AUTOSAR XML (schema 00048)
package /HuaweiMDC/PlatformApplication/UssCmCenterApplication/Execution
  executable libuss_a_cm
    root sw component prototype uss_a_cm: application-type=libuss_a_cm
package /HuaweiMDC/PlatformApplication/UssCmCenterApplication/SwComponent
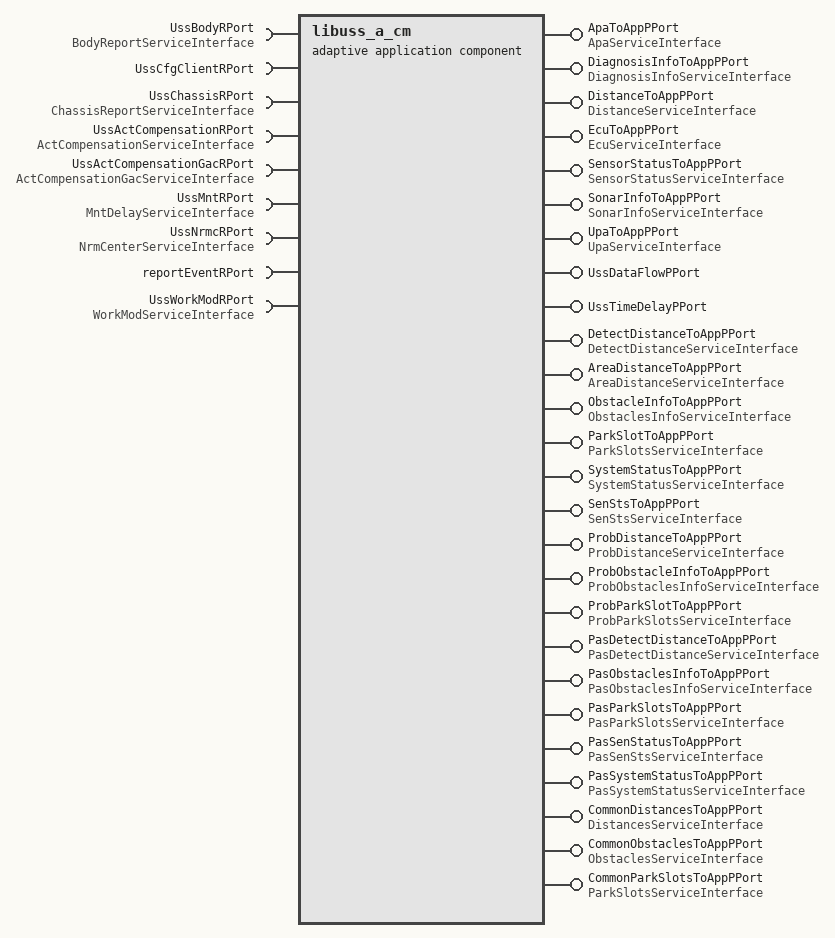
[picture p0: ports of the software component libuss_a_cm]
  adaptive application sw component type libuss_a_cm
    7 x provide port:
      ApaToAppPPort: provided-interface=ApaServiceInterface
      DiagnosisInfoToAppPPort: provided-interface=DiagnosisInfoServiceInterface
      DistanceToAppPPort: provided-interface=DistanceServiceInterface
      EcuToAppPPort: provided-interface=EcuServiceInterface
      SensorStatusToAppPPort: provided-interface=SensorStatusServiceInterface
      SonarInfoToAppPPort: provided-interface=SonarInfoServiceInterface
      UpaToAppPPort: provided-interface=UpaServiceInterface
    5 x require port:
      UssBodyRPort: required-interface=BodyReportServiceInterface
      UssCfgClientRPort
      UssChassisRPort: required-interface=ChassisReportServiceInterface
      UssActCompensationRPort: required-interface=ActCompensationServiceInterface
      UssActCompensationGacRPort: required-interface=ActCompensationGacServiceInterface
    provide port UssDataFlowPPort
    require port UssMntRPort: required-interface=MntDelayServiceInterface
    require port UssNrmcRPort: required-interface=NrmCenterServiceInterface
    provide port UssTimeDelayPPort
    require port reportEventRPort
    5 x provide port:
      DetectDistanceToAppPPort: provided-interface=DetectDistanceServiceInterface
      AreaDistanceToAppPPort: provided-interface=AreaDistanceServiceInterface
      ObstacleInfoToAppPPort: provided-interface=ObstaclesInfoServiceInterface
      ParkSlotToAppPPort: provided-interface=ParkSlotsServiceInterface
      SystemStatusToAppPPort: provided-interface=SystemStatusServiceInterface
    require port UssWorkModRPort: required-interface=WorkModServiceInterface
    12 x provide port:
      SenStsToAppPPort: provided-interface=SenStsServiceInterface
      ProbDistanceToAppPPort: provided-interface=ProbDistanceServiceInterface
      ProbObstacleInfoToAppPPort: provided-interface=ProbObstaclesInfoServiceInterface
      ProbParkSlotToAppPPort: provided-interface=ProbParkSlotsServiceInterface
      PasDetectDistanceToAppPPort: provided-interface=PasDetectDistanceServiceInterface
      PasObstaclesInfoToAppPPort: provided-interface=PasObstaclesInfoServiceInterface
      PasParkSlotsToAppPPort: provided-interface=PasParkSlotsServiceInterface
      PasSenStatusToAppPPort: provided-interface=PasSenStsServiceInterface
      PasSystemStatusToAppPPort: provided-interface=PasSystemStatusServiceInterface
      CommonDistancesToAppPPort: provided-interface=DistancesServiceInterface
      CommonObstaclesToAppPPort: provided-interface=ObstaclesServiceInterface
      CommonParkSlotsToAppPPort: provided-interface=ParkSlotsServiceInterface
  composition sw component type uss_a
    component diag_agent: type=diag_agent
    component uss_a_cm: type=libuss_a_cm
package /HuaweiMDC/PlatformApplication/UssCmCenterApplication/UssProcessStartupConfig
  startup config set UssStartupConfigSet
    startup config UssStartupConfig: scheduling-policy=SCHEDULING-POLICY-ROUND-ROBIN, scheduling-priority=12
